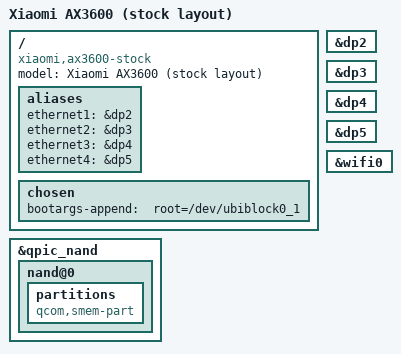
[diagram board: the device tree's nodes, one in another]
// SPDX-License-Identifier: GPL-2.0-or-later OR MIT

/dts-v1/;

#include "ipq8071-ax3600.dts"

/ {
	model = "Xiaomi AX3600 (stock layout)";
	compatible = "xiaomi,ax3600-stock", "qcom,ipq8074";

	aliases {
		ethernet1 = &dp2;
		ethernet2 = &dp3;
		ethernet3 = &dp4;
		ethernet4 = &dp5;
	};

	chosen {
		bootargs-append = " root=/dev/ubiblock0_1";
	};
};

&qpic_nand {
	/delete-node/ partitions;

	nand@0 {
		/delete-node/ partitions;

		partitions {
			compatible = "qcom,smem-part";
		};
	};
};

&dp2 {
	/delete-property/ nvmem-cells;
	/delete-property/ nvmem-cell-names;
};

&dp3 {
	/delete-property/ nvmem-cells;
	/delete-property/ nvmem-cell-names;
};

&dp4 {
	/delete-property/ nvmem-cells;
	/delete-property/ nvmem-cell-names;
};

&dp5 {
	/delete-property/ nvmem-cells;
	/delete-property/ nvmem-cell-names;
};

&wifi0 {
	/delete-property/ nvmem-cells;
	/delete-property/ nvmem-cell-names;
};
